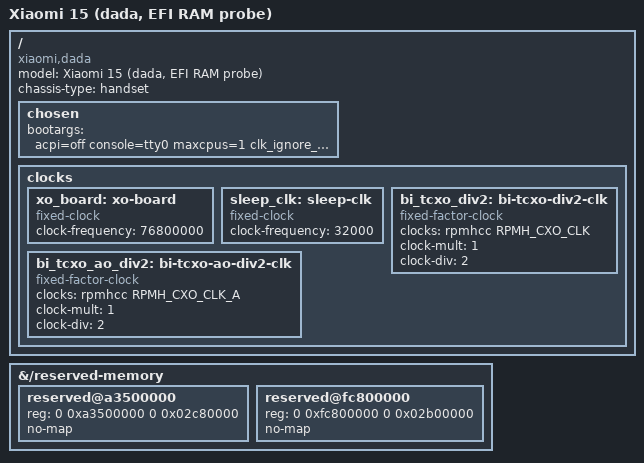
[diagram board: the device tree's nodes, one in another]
// SPDX-License-Identifier: BSD-3-Clause
/dts-v1/;
#include "sm8750.dtsi"

/ {
	model = "Xiaomi 15 (dada, EFI RAM probe)";
	compatible = "xiaomi,dada", "qcom,sm8750";
	chassis-type = "handset";
	// Do not describe a donor phone's RAM banks. EFI supplies usable memory.
	chosen { bootargs = "acpi=off console=tty0 maxcpus=1 clk_ignore_unused pd_ignore_unused regulator_ignore_unused panic=10 rdinit=/init"; };
	clocks {
		xo_board: xo-board { compatible = "fixed-clock"; #clock-cells = <0>; clock-frequency = <76800000>; };
		sleep_clk: sleep-clk { compatible = "fixed-clock"; #clock-cells = <0>; clock-frequency = <32000>; };
		bi_tcxo_div2: bi-tcxo-div2-clk {
			compatible = "fixed-factor-clock"; #clock-cells = <0>;
			clocks = <&rpmhcc RPMH_CXO_CLK>; clock-mult = <1>; clock-div = <2>;
		};
		bi_tcxo_ao_div2: bi-tcxo-ao-div2-clk {
			compatible = "fixed-factor-clock"; #clock-cells = <0>;
			clocks = <&rpmhcc RPMH_CXO_CLK_A>; clock-mult = <1>; clock-div = <2>;
		};
	};
};
// Keep the vendor display/crash buffers out of the allocator as in dadaPkg's
// MemoryMapLib. Use GOP, not an unverified DSI/panel power sequence.
&{/reserved-memory} {
	reserved@a3500000 { reg = <0 0xa3500000 0 0x02c80000>; no-map; };
	reserved@fc800000 { reg = <0 0xfc800000 0 0x02b00000>; no-map; };
};
